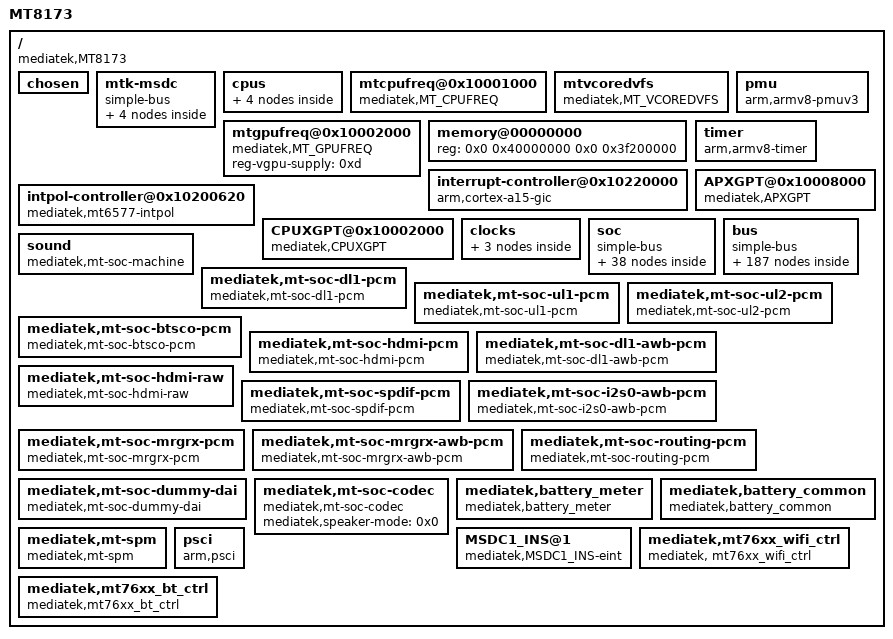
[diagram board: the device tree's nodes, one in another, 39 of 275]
/dts-v1/;

/memreserve/	0x0000000041e00000 0x0000000000a00000;
/memreserve/	0x0000000043f00000 0x0000000000010000;
/memreserve/	0x0000000043ff0000 0x0000000000010000;
/ {
	model = "MT8173";
	compatible = "mediatek,MT8173";
	interrupt-parent = <0x1>;
	#address-cells = <0x2>;
	#size-cells = <0x2>;

	chosen {
		bootargs = "console=tty0 console=ttyMT0,921600n1 root=/dev/ram initrd=0x44000000,0x600000 loglevel=8";
	};

	mtk-msdc {
		compatible = "simple-bus";
		#address-cells = <0x1>;
		#size-cells = <0x1>;
		ranges = <0x0 0x0 0x0 0xffffffff>;

		MSDC0@0x11230000 {
			compatible = "mediatek,MSDC0";
			reg = <0x11230000 0x10000 0x10001e84 0x2>;
			interrupts = <0x0 0x47 0x8>;
			msdc0-vemc-supply = <0x2>;
			#msdc0-vio18-supply = <0x3>;
			clocks = <0x4 0xe 0x5 0x26 0x6 0xe>;
			clock-names = "source", "mux_parent", "msdcpll2";
			id = <0x0>;
			status = "okay";
		};

		MSDC1@0x11240000 {
			compatible = "mediatek,MSDC1";
			reg = <0x11240000 0x10000 0x10001e84 0x2>;
			interrupts = <0x0 0x48 0x8>;
			msdc1-vmc-supply = <0x7>;
			msdc1-vmch-supply = <0x8>;
			clocks = <0x4 0xf>;
			clock-names = "source";
			id = <0x1>;
			status = "okay";
		};

		MSDC2@0x11250000 {
			compatible = "mediatek,MSDC2";
			reg = <0x11250000 0x10000 0x10001e84 0x2>;
			interrupts = <0x0 0x49 0x8>;
			msdc2-vmc-supply = <0x7>;
			msdc2-vmch-supply = <0x8>;
			clocks = <0x4 0x10>;
			clock-names = "source";
			id = <0x2>;
			status = "disabled";
		};

		MSDC3@0x11260000 {
			compatible = "mediatek,MSDC3";
			reg = <0x11260000 0x10000 0x10001e84 0x2>;
			interrupts = <0x0 0x4a 0x8>;
			clocks = <0x4 0x11>;
			clock-names = "source";
			id = <0x3>;
			status = "disabled";
		};
	};

	cpus {
		#address-cells = <0x1>;
		#size-cells = <0x0>;

		cpu@0 {
			device_type = "cpu";
			compatible = "arm,cortex-a53";
			reg = <0x0>;
			enable-method = "mt-boot";
			cpu-release-addr = <0x0 0x40000200>;
			clock-frequency = <0x3b9aca00>;
		};

		cpu@1 {
			device_type = "cpu";
			compatible = "arm,cortex-a53";
			reg = <0x1>;
			enable-method = "mt-boot";
			cpu-release-addr = <0x0 0x40000200>;
			clock-frequency = <0x3b9aca00>;
		};

		cpu@2 {
			device_type = "cpu";
			compatible = "arm,cortex-a57";
			reg = <0x100>;
			enable-method = "mt-boot";
			cpu-release-addr = <0x0 0x40000200>;
			clock-frequency = <0x3b9aca00>;
		};

		cpu@3 {
			device_type = "cpu";
			compatible = "arm,cortex-a57";
			reg = <0x101>;
			enable-method = "mt-boot";
			cpu-release-addr = <0x0 0x40000200>;
			clock-frequency = <0x3b9aca00>;
		};
	};

	mtcpufreq@0x10001000 {
		compatible = "mediatek,MT_CPUFREQ";
		reg-vpca53-supply = <0x9>;
		reg-ext-vpca57-supply = <0xa>;
		reg-vsramca57-supply = <0xb>;
		reg-vcore-supply = <0xc>;
		reg-vgpu-supply = <0xd>;
		clocks = <0x6 0x1>;
		clock-names = "mtcpufreq_apmixed_ca15pll";
	};

	mtvcoredvfs {
		compatible = "mediatek,MT_VCOREDVFS";
		reg-vcore-supply = <0xc>;
		clocks = <0x6 0x7 0x6 0xa 0x6 0x5 0x5 0x52 0x5 0x69 0x5 0x6c 0x5 0x3e 0x5 0x3f 0x5 0x43 0x5 0x2b 0x5 0x2c 0x5 0x4e 0x5 0x54 0x5 0x2e 0xe 0x5 0x67>;
		clock-names = "vencpll", "vcodecpll", "mmpll", "axi_sel", "venclt_sel", "cci400_sel", "univpll_d2", "univpll1_d2", "univpll2_d2", "syspll_d2", "syspll1_d2", "vcodecpll_370p5", "ddrphycfg_sel", "syspll1_d8", "clk26m", "scp_sel";
	};

	mtgpufreq@0x10002000 {
		compatible = "mediatek,MT_GPUFREQ";
		reg-vgpu-supply = <0xd>;
	};

	memory@00000000 {
		device_type = "memory";
		reg = <0x0 0x40000000 0x0 0x3f200000>;
	};

	pmu {
		compatible = "arm,armv8-pmuv3";
		interrupts = <0x0 0x8 0x4 0x0 0x9 0x4 0x0 0xa 0x4 0x0 0xb 0x4 0x0 0xc 0x4 0x0 0xd 0x4 0x0 0xe 0x4 0x0 0xf 0x4>;
	};

	interrupt-controller@0x10220000 {
		compatible = "arm,cortex-a15-gic", "arm,cortex-a9-gic";
		#interrupt-cells = <0x3>;
		#address-cells = <0x0>;
		interrupt-controller;
		reg = <0x0 0x10221000 0x0 0x1000 0x0 0x10222000 0x0 0x1000 0x0 0x10200620 0x0 0x1000>;
		interrupts = <0x1 0x9 0xf04>;
		linux,phandle = <0x1>;
		phandle = <0x1>;
	};

	intpol-controller@0x10200620 {
		compatible = "mediatek,mt6577-intpol";
		reg = <0x0 0x10200620 0x0 0x1000>;
		interrupt-controller;
	};

	CPUXGPT@0x10002000 {
		compatible = "mediatek,CPUXGPT";
		reg = <0x0 0x10200000 0x0 0x1000>;
		interrupts = <0x0 0x38 0x4 0x0 0x39 0x4 0x0 0x3a 0x4 0x0 0x3b 0x4 0x0 0x3c 0x4 0x0 0x3d 0x4 0x0 0x3e 0x4 0x0 0x3f 0x4>;
	};

	timer {
		compatible = "arm,armv8-timer";
		interrupts = <0x1 0xd 0x8 0x1 0xe 0x8 0x1 0xb 0x8 0x1 0xa 0x8>;
		clock-frequency = <0xc65d40>;
	};

	APXGPT@0x10008000 {
		compatible = "mediatek,APXGPT";
		reg = <0x0 0x10008000 0x0 0x1000>;
		interrupts = <0x0 0x90 0x8>;
		clock-frequency = <0xc65d40>;
	};

	clocks {

		clk_null {
			compatible = "fixed-clock";
			#clock-cells = <0x0>;
			clock-frequency = <0x0>;
		};

		clk26m {
			compatible = "fixed-clock";
			#clock-cells = <0x0>;
			clock-frequency = <0x18cba80>;
			linux,phandle = <0xe>;
			phandle = <0xe>;
		};

		clk32k {
			compatible = "fixed-clock";
			#clock-cells = <0x0>;
			clock-frequency = <0x7d00>;
		};
	};

	soc {
		compatible = "simple-bus";
		#address-cells = <0x2>;
		#size-cells = <0x2>;
		ranges;

		topckgen@10000000 {
			compatible = "mediatek,mt8173-topckgen";
			reg = <0x0 0x10000000 0x0 0x1000>;
			#clock-cells = <0x1>;
			linux,phandle = <0x5>;
			phandle = <0x5>;
		};

		infrasys@10001000 {
			compatible = "mediatek,mt8173-infrasys";
			reg = <0x0 0x10001000 0x0 0x1000>;
			#clock-cells = <0x1>;
			linux,phandle = <0x12>;
			phandle = <0x12>;
		};

		perisys@10003000 {
			compatible = "mediatek,mt8173-perisys";
			reg = <0x0 0x10003000 0x0 0x1000>;
			#clock-cells = <0x1>;
			linux,phandle = <0x4>;
			phandle = <0x4>;
		};

		apmixedsys@10209000 {
			compatible = "mediatek,mt8173-apmixedsys";
			reg = <0x0 0x10209000 0x0 0x1000>;
			#clock-cells = <0x1>;
			linux,phandle = <0x6>;
			phandle = <0x6>;
		};

		audiosys@112200000 {
			compatible = "mediatek,mt8173-audiosys";
			reg = <0x0 0x11220000 0x0 0x1000>;
			#clock-cells = <0x1>;
			linux,phandle = <0x1c>;
			phandle = <0x1c>;
		};

		mfgsys@13fff000 {
			compatible = "mediatek,mt8173-mfgsys";
			reg = <0x0 0x13fff000 0x0 0x1000>;
			#clock-cells = <0x1>;
			linux,phandle = <0x16>;
			phandle = <0x16>;
		};

		mmsys@14000000 {
			compatible = "mediatek,mt8173-mmsys";
			reg = <0x0 0x14000000 0x0 0x1000>;
			#clock-cells = <0x1>;
			linux,phandle = <0x13>;
			phandle = <0x13>;
		};

		imgsys@15000000 {
			compatible = "mediatek,mt8173-imgsys";
			reg = <0x0 0x15000000 0x0 0x1000>;
			#clock-cells = <0x1>;
			linux,phandle = <0x19>;
			phandle = <0x19>;
		};

		vdecsys@16000000 {
			compatible = "mediatek,mt8173-vdecsys";
			reg = <0x0 0x16000000 0x0 0x1000>;
			#clock-cells = <0x1>;
			linux,phandle = <0x18>;
			phandle = <0x18>;
		};

		vencsys@18000000 {
			compatible = "mediatek,mt8173-vencsys";
			reg = <0x0 0x18000000 0x0 0x1000>;
			#clock-cells = <0x1>;
			linux,phandle = <0x1a>;
			phandle = <0x1a>;
		};

		vencltsys@19000000 {
			compatible = "mediatek,mt8173-vencltsys";
			reg = <0x0 0x19000000 0x0 0x1000>;
			#clock-cells = <0x1>;
			linux,phandle = <0x1b>;
			phandle = <0x1b>;
		};

		scpsys@10001000 {
			compatible = "mediatek,mt8173-scpsys";
			reg = <0x0 0x10001000 0x0 0x1000 0x0 0x10006000 0x0 0x1000 0x0 0x13fff000 0x0 0x1000>;
			#clock-cells = <0x1>;
			linux,phandle = <0x14>;
			phandle = <0x14>;
		};

		pmic {
			compatible = "mediatek,mt6397";
			interrupt-parent = <0xf>;
			interrupts = <0x5 0x4>;

			mediatek,pmic-mt6397 {
				compatible = "mediatek,pmic-mt6397";
			};

			regulators {

				buck_vpca15 {
					regulator-name = "vpca15";
					regulator-min-microvolt = <0xaae60>;
					regulator-max-microvolt = <0x16caf6>;
					regulator-ramp-delay = <0x30d4>;
					regulator-enable-ramp-delay = <0xc8>;
					regulator-always-on;
					regulator-boot-on;
					linux,phandle = <0x9>;
					phandle = <0x9>;
				};

				buck_vpca7 {
					regulator-name = "vpca7";
					regulator-min-microvolt = <0xaae60>;
					regulator-max-microvolt = <0x16caf6>;
					regulator-ramp-delay = <0x30d4>;
					regulator-enable-ramp-delay = <0x73>;
					regulator-always-on;
					regulator-boot-on;
				};

				buck_vsramca15 {
					regulator-name = "vsramca15";
					regulator-min-microvolt = <0xaae60>;
					regulator-max-microvolt = <0x16caf6>;
					regulator-ramp-delay = <0x30d4>;
					regulator-enable-ramp-delay = <0x73>;
					regulator-always-on;
					regulator-boot-on;
				};

				buck_vsramca7 {
					regulator-name = "vsramca7";
					regulator-min-microvolt = <0xaae60>;
					regulator-max-microvolt = <0x16caf6>;
					regulator-ramp-delay = <0x30d4>;
					regulator-enable-ramp-delay = <0xd7>;
					regulator-boot-on;
					linux,phandle = <0xb>;
					phandle = <0xb>;
				};

				buck_vcore {
					regulator-name = "vcore";
					regulator-min-microvolt = <0xaae60>;
					regulator-max-microvolt = <0x16caf6>;
					regulator-ramp-delay = <0x30d4>;
					regulator-enable-ramp-delay = <0x73>;
					regulator-always-on;
					regulator-boot-on;
					linux,phandle = <0xc>;
					phandle = <0xc>;
				};

				buck_vgpu {
					regulator-name = "vgpu";
					regulator-min-microvolt = <0xaae60>;
					regulator-max-microvolt = <0x16caf6>;
					regulator-ramp-delay = <0x30d4>;
					regulator-enable-ramp-delay = <0x73>;
				};

				buck_vdrm {
					regulator-name = "vdrm";
					regulator-min-microvolt = <0xc3500>;
					regulator-max-microvolt = <0x185196>;
					regulator-ramp-delay = <0x30d4>;
					regulator-enable-ramp-delay = <0x1f4>;
					regulator-always-on;
					regulator-boot-on;
				};

				buck_vio18 {
					regulator-name = "vio18";
					regulator-min-microvolt = <0x1b7740>;
					regulator-max-microvolt = <0x1b7740>;
					regulator-ramp-delay = <0x30d4>;
					regulator-enable-ramp-delay = <0x1f4>;
					regulator-always-on;
					regulator-boot-on;
					linux,phandle = <0x3>;
					phandle = <0x3>;
				};

				ldo_vtcxo {
					regulator-name = "vtcxo";
					regulator-min-microvolt = <0x2ab980>;
					regulator-max-microvolt = <0x2ab980>;
					regulator-enable-ramp-delay = <0x5a>;
					regulator-always-on;
					regulator-boot-on;
				};

				ldo_va28 {
					regulator-name = "va28";
					regulator-min-microvolt = <0x2ab980>;
					regulator-max-microvolt = <0x2ab980>;
					regulator-enable-ramp-delay = <0xda>;
					regulator-always-on;
					regulator-boot-on;
				};

				ldo_vcama {
					regulator-name = "vcama";
					regulator-min-microvolt = <0x16e360>;
					regulator-max-microvolt = <0x2ab980>;
					regulator-enable-ramp-delay = <0xda>;
				};

				ldo_vio28 {
					regulator-name = "vio28";
					regulator-min-microvolt = <0x2ab980>;
					regulator-max-microvolt = <0x2ab980>;
					regulator-enable-ramp-delay = <0xf0>;
					regulator-always-on;
					regulator-boot-on;
				};

				ldo_usb {
					regulator-name = "usb";
					regulator-min-microvolt = <0x325aa0>;
					regulator-max-microvolt = <0x325aa0>;
					regulator-enable-ramp-delay = <0xda>;
					linux,phandle = <0x17>;
					phandle = <0x17>;
				};

				ldo_vmc {
					regulator-name = "vmc";
					regulator-min-microvolt = <0x1b7740>;
					regulator-max-microvolt = <0x325aa0>;
					regulator-enable-ramp-delay = <0xda>;
					linux,phandle = <0x7>;
					phandle = <0x7>;
				};

				ldo_vmch {
					regulator-name = "vmch";
					regulator-min-microvolt = <0x2dc6c0>;
					regulator-max-microvolt = <0x325aa0>;
					regulator-enable-ramp-delay = <0xda>;
					linux,phandle = <0x8>;
					phandle = <0x8>;
				};

				ldo_vemc3v3 {
					regulator-name = "vemc_3v3";
					regulator-min-microvolt = <0x2dc6c0>;
					regulator-max-microvolt = <0x325aa0>;
					regulator-enable-ramp-delay = <0xda>;
					regulator-boot-on;
					linux,phandle = <0x2>;
					phandle = <0x2>;
				};

				ldo_vcamd {
					regulator-name = "vgp1";
					regulator-min-microvolt = <0x129da0>;
					regulator-max-microvolt = <0x325aa0>;
					regulator-enable-ramp-delay = <0xf0>;
					regulator-always-on;
					regulator-boot-on;
				};

				ldo_vcamio {
					regulator-name = "vgp2";
					regulator-min-microvolt = <0x124f80>;
					regulator-max-microvolt = <0x325aa0>;
					regulator-enable-ramp-delay = <0xda>;
				};

				ldo_vcamaf {
					regulator-name = "vgp3";
					regulator-min-microvolt = <0x124f80>;
					regulator-max-microvolt = <0x325aa0>;
					regulator-enable-ramp-delay = <0xda>;
				};

				ldo_vgp4 {
					regulator-name = "vgp4";
					regulator-min-microvolt = <0x124f80>;
					regulator-max-microvolt = <0x325aa0>;
					regulator-enable-ramp-delay = <0xda>;
				};

				ldo_vgp5 {
					regulator-name = "vgp5";
					regulator-min-microvolt = <0x124f80>;
					regulator-max-microvolt = <0x2dc6c0>;
					regulator-enable-ramp-delay = <0xda>;
				};

				ldo_vgp6 {
					regulator-name = "vgp6";
					regulator-min-microvolt = <0x124f80>;
					regulator-max-microvolt = <0x325aa0>;
					regulator-enable-ramp-delay = <0xda>;
				};

				ldo_vibr {
					regulator-name = "vibr";
					regulator-min-microvolt = <0x124f80>;
					regulator-max-microvolt = <0x325aa0>;
					regulator-enable-ramp-delay = <0xda>;
				};
			};
		};
	};

	bus {
		compatible = "simple-bus";
		#address-cells = <0x1>;
		#size-cells = <0x1>;
		ranges = <0x0 0x0 0x0 0xffffffff>;

		CHIPID@08000000 {
			compatible = "mediatek,CHIPID";
			reg = <0x8000000 0x10>;
		};

		TOPCKGEN@0x10000000 {
			compatible = "mediatek,TOPCKGEN";
			reg = <0x10000000 0x1000>;
		};

		INFRACFG_AO@0x10001000 {
			compatible = "mediatek,INFRACFG_AO";
			reg = <0x10001000 0x1000>;
		};

		IOCFG_L@0x10002000 {
			compatible = "mediatek,IOCFG_L";
			reg = <0x10002000 0x400>;
		};

		IOCFG_B@0x10002400 {
			compatible = "mediatek,IOCFG_B";
			reg = <0x10002400 0x400>;
		};

		IOCFG_R@0x10002800 {
			compatible = "mediatek,IOCFG_R";
			reg = <0x10002800 0x400>;
		};

		IOCFG_T@0x10002C00 {
			compatible = "mediatek,IOCFG_T";
			reg = <0x10002c00 0x400>;
		};

		PERICFG@0x10003000 {
			compatible = "mediatek,PERICFG";
			reg = <0x10003000 0x1000>;
		};

		DRAMC0@0x10004000 {
			compatible = "mediatek,DRAMC0";
			reg = <0x10004000 0x1000>;
		};

		DRAMC1@0x10011000 {
			compatible = "mediatek,DRAMC1";
			reg = <0x10011000 0x1000>;
		};

		GPIO@0x10005000 {
			compatible = "mediatek,GPIO";
			reg = <0x10005000 0xe70>;
		};

		pcfg_pull_none {
			bias-disable;
		};

		pcfg_pull_down {
			bias-pull-down;
		};

		pcfg_pull_up {
			bias-pull-up;
			linux,phandle = <0x11>;
			phandle = <0x11>;
		};

		pcfg_output_low {
			output-low;
		};

		pcfg_output_high {
			output-high;
		};

		pcfg_input_enable {
			input-enable;
		};

		pcfg_input_disable {
			input-disable;
		};

		pcfg_input_pulldisable {
			input-enable;
			bias-disable;
		};

		pcfg_input_pullup {
			input-enable;
			bias-pull-up;
		};

		pcfg_input_pulldown {
			input-enable;
			bias-pull-down;
		};

		pinctrl@0x10005000 {
			compatible = "mediatek,mt8173-pinctrl";
			reg = <0x10005000 0x1000>;
			gpio-controller;
			#gpio-cells = <0x2>;
			pinctrl-names = "default";
			pinctrl-0 = <0x10>;

			pinctrl@0x10005000 {
				linux,phandle = <0x10>;
				phandle = <0x10>;
			};

			bt_wake_up {
				mediatek,pins = <0x6400 0x11>;
				linux,phandle = <0x1d>;
				phandle = <0x1d>;
			};
		};

		pinctrl@0x0000C000 {
			compatible = "mediatek,mt6397-pinctrl";
			reg = <0xc000 0x108>;
			gpio-controller;
			#gpio-cells = <0x2>;
			linux,phandle = <0x15>;
			phandle = <0x15>;
		};

		SLEEP@0x10006000 {
			compatible = "mediatek,SLEEP";
			reg = <0x10006000 0x1000>;
			interrupts = <0x0 0x9b 0x8 0x0 0x9c 0x8 0x0 0x9d 0x8 0x0 0x9e 0x8 0x0 0x9f 0x8 0x0 0xa0 0x8>;
		};

		TOPRGU@0x10007000 {
			compatible = "mediatek,TOPRGU";
			reg = <0x10007000 0x1000>;
			interrupts = <0x0 0x78 0x2>;
		};

		RSVD@0x10009000 {
			compatible = "mediatek,RSVD";
			reg = <0x10009000 0x1000>;
		};

		SEJ@0x1000A000 {
			compatible = "mediatek,SEJ";
			reg = <0x1000a000 0x1000>;
			interrupts = <0x0 0xa3 0x8>;
		};

		EINTC@0x1000B000 {
			compatible = "mediatek,EINTC";
			reg = <0x1000b000 0x1000>;
			interrupts = <0x0 0x91 0x4>;
			#interrupt-cells = <0x2>;
			interrupt-controller;
			linux,phandle = <0xf>;
			phandle = <0xf>;
		};

		APMIXED@0x10209000 {
			compatible = "mediatek,APMIXED";
			reg = <0x10209000 0x1000>;
			interrupts = <0x0 0x81 0x1>;
		};

		FHCTL@0x10209E00 {
			compatible = "mediatek,FHCTL";
			reg = <0x10209e00 0x100>;
		};

		PWRAP@0x1000D000 {
			compatible = "mediatek,PWRAP";
			reg = <0x1000d000 0x1000>;
			interrupts = <0x0 0x99 0x4>;
		};

		DEVAPC_AO@0x1000E000 {
			compatible = "mediatek,DEVAPC_AO";
			reg = <0x1000e000 0x1000>;
		};

		DDRPHY0@0x1000F000 {
			compatible = "mediatek,DDRPHY0";
			reg = <0x1000f000 0x1000>;
		};

		DDRPHY1@0x10012000 {
			compatible = "mediatek,DDRPHY1";
			reg = <0x10012000 0x1000>;
		};

		CQDMA@0x10212C00 {
			compatible = "mediatek,CQDMA";
			reg = <0x10212c00 0x1000>;
			interrupts = <0x0 0x8f 0x8>;
			nr_channel = <0x1>;
		};

		KP@0x10010000 {
			compatible = "mediatek,KP";
			reg = <0x10010000 0x1000>;
			interrupts = <0x0 0x9a 0x2>;
		};

		TOPMISC@0x10011000 {
			compatible = "mediatek,TOPMISC";
			reg = <0x10011000 0x1000>;
		};

		SCP_SRAM@0x10020000 {
			compatible = "mediatek,SCP_SRAM";
			reg = <0x10020000 0x30000>;
		};

		SCP_CFGREG@0x10050000 {
			compatible = "mediatek,SCP_CFGREG";
			reg = <0x10050000 0x90>;
			interrupts = <0x0 0xa6 0x4>;
		};

		DBG_ETB@0x10100000 {
			compatible = "mediatek,DBG_ETB";
			reg = <0x10410000 0x10000 0x10430000 0x10000 0x10440000 0x10000 0x104a0000 0x10000>;
		};

		DBG_DEBUG {
			compatible = "mediatek,DBG_DEBUG";
			num = <0x8>;
			reg = <0x10810000 0x1000 0x10910000 0x1000 0x10a10000 0x1000 0x10b10000 0x1000 0x10c10000 0x1000 0x10d10000 0x1000 0x10e10000 0x1000 0x10f10000 0x1000>;
		};

		DBG_ETM {
			compatible = "mediatek,DBG_ETM";
			num = <0x8>;
			reg = <0x10840000 0x1000 0x10940000 0x1000 0x10a40000 0x1000 0x10b40000 0x1000 0x10c40000 0x1000 0x10d40000 0x1000 0x10e40000 0x1000 0x10f40000 0x1000>;
		};

		MCUCFG@0x10200000 {
			compatible = "mediatek,MCUCFG";
			reg = <0x10200000 0x1000>;
		};

		INFRACFG@0x10201000 {
			compatible = "mediatek,INFRACFG";
			reg = <0x10201000 0x1000>;
		};

		SRAMROM@0x10202000 {
			compatible = "mediatek,SRAMROM";
			reg = <0x10202000 0x1000>;
		};

		EMI@0x10203000 {
			compatible = "mediatek,EMI";
			reg = <0x10203000 0x1000>;
			interrupts = <0x0 0x80 0x8>;
		};

		SYS_CIRQ@0x10204000 {
			compatible = "mediatek,SYS_CIRQ";
			reg = <0x10204000 0x1000>;
		};

		M4U@0x10205000 {
			cell-index = <0x0>;
			compatible = "mediatek,M4U";
			reg = <0x10205000 0x1000>;
			interrupts = <0x0 0x8b 0x8>;
			clocks = <0x12 0x6 0x12 0x2>;
			clock-names = "infra_m4u", "infra_smi";
		};

		EFUSEC@0x10206000 {
			compatible = "mediatek,EFUSEC";
			reg = <0x10206000 0x1000>;
			interrupts = <0x0 0x82 0x1>;
		};

		DEVAPC@0x10207000 {
			compatible = "mediatek,DEVAPC";
			reg = <0x10207000 0x1000>;
			interrupts = <0x0 0x7e 0x8>;
		};

		BUS_DBG@0x10208000 {
			compatible = "mediatek,BUS_DBG";
			reg = <0x10208000 0x1000>;
			interrupts = <0x0 0x7d 0x8>;
		};

		AP_CCIF0@0x10209000 {
			compatible = "mediatek,AP_CCIF0";
			reg = <0x10209000 0x1000>;
			interrupts = <0x0 0x84 0x8>;
		};

		INFRA_MBIST@0x1020D000 {
			compatible = "mediatek,INFRA_MBIST";
			reg = <0x1020d000 0x1000>;
		};

		DRAMC0_NAO@0x1020E000 {
			compatible = "mediatek,DRAMC0_NAO";
			reg = <0x1020e000 0x1000>;
		};

		DRAMC1_NAO@0x10213000 {
			compatible = "mediatek,DRAMC1_NAO";
			reg = <0x10213000 0x1000>;
		};

		EMI_DVFS_SRAM@0x0012FC00 {
			compatible = "mediatek,EMI_DVFS_SRAM";
			reg = <0x12fc00 0x400>;
		};

		TRNG@0x1020F000 {
			compatible = "mediatek,TRNG";
			reg = <0x1020f000 0x1000>;
			interrupts = <0x0 0x85 0x8>;
		};

		GCPU@0x10210000 {
			compatible = "mediatek,GCPU";
			reg = <0x10210000 0x1000>;
			interrupts = <0x0 0x8e 0x8>;
		};

		MD2MD_MD1_CCIF0@0x10211000 {
			compatible = "mediatek,MD2MD_MD1_CCIF0";
			reg = <0x10211000 0x1000>;
		};

		GCE@0x10212000 {
			compatible = "mediatek,GCE";
			reg = <0x10212000 0x1000>;
			interrupts = <0x0 0x87 0x8 0x0 0x88 0x8>;
			clocks = <0x12 0x4 0x13 0xf 0x13 0x1 0x13 0x2 0x13 0x32 0x13 0x3 0x13 0x4 0x13 0x5 0x13 0x6 0x13 0x7 0x13 0x8 0x13 0x9 0x13 0xa 0x13 0xc 0x13 0xd 0x13 0xb 0x14 0x1 0x14 0x4 0x14 0x5>;
			clock-names = "MT_CG_INFRA_GCE", "MT_CG_DISP0_MUTEX_32K", "MT_CG_DISP0_SMI_COMMON", "MT_CG_DISP0_SMI_LARB0", "MT_CG_DISP0_SMI_LARB4", "MT_CG_DISP0_CAM_MDP", "MT_CG_DISP0_MDP_RDMA0", "MT_CG_DISP0_MDP_RDMA1", "MT_CG_DISP0_MDP_RSZ0", "MT_CG_DISP0_MDP_RSZ1", "MT_CG_DISP0_MDP_RSZ2", "MT_CG_DISP0_MDP_TDSHP0", "MT_CG_DISP0_MDP_TDSHP1", "MT_CG_DISP0_MDP_WROT0", "MT_CG_DISP0_MDP_WROT1", "MT_CG_DISP0_MDP_WDMA", "sys_vde", "sys_isp", "sys_dis";
		};

		MD2MD_MD2_CCIF0@0x10213000 {
			compatible = "mediatek,MD2MD_MD2_CCIF0";
			reg = <0x10213000 0x1000>;
		};

		PERISYS_IOMMU@0x10214000 {
			cell-index = <0x1>;
			compatible = "mediatek,PERISYS_IOMMU";
			reg = <0x10214000 0x1000>;
			interrupts = <0x0 0x89 0x8>;
		};

		MIPI_TX0@0x10215000 {
			compatible = "mediatek,MIPI_TX0";
			reg = <0x10215000 0x1000>;
		};

		MIPI_RX_ANA_CSI0@0x10217000 {
			compatible = "mediatek,MIPI_RX_ANA_CSI0";
			reg = <0x10217000 0x1000>;
			interrupts = <0x0 0x6a 0x1>;
		};

		MIPI_RX_ANA_CSI1@0x10218000 {
			compatible = "mediatek,MIPI_RX_ANA_CSI1";
			reg = <0x10218000 0x1000>;
		};

		GIC@0x10220000 {
			compatible = "mediatek,GIC";
			reg = <0x10220000 0x8000>;
		};

		CCI400@0x10390000 {
			compatible = "mediatek,CCI400";
			reg = <0x10390000 0x10000>;
		};

		DBGAPB@0x10400000 {
			compatible = "mediatek,DBGAPB";
			reg = <0x10400000 0xc00000>;
			interrupts = <0x0 0x63 0x8>;
		};

		AP_DMA@0x11000000 {
			compatible = "mediatek,AP_DMA";
			reg = <0x11000000 0x1000>;
			interrupts = <0x0 0x59 0x8>;
		};

		AUXADC@0x11001000 {
			compatible = "mediatek,AUXADC";
			reg = <0x11001000 0x1000>;
			interrupts = <0x0 0x44 0x2>;
			clocks = <0x4 0x1d>;
			clock-names = "auxadc_clk";
		};

		AP_DMA_UART0_TX@0x11000300 {
			compatible = "mediatek,AP_DMA_UART0_TX";
			reg = <0x11000300 0x80>;
			interrupts = <0x0 0x5f 0x8>;
			clocks = <0x4 0xd>;
			clock-names = "MT_CG_PERI_dma";
		};

		AP_DMA_UART0_RX@0x11000380 {
			compatible = "mediatek,AP_DMA_UART0_RX";
			reg = <0x11000380 0x80>;
			interrupts = <0x0 0x60 0x8>;
			clocks = <0x4 0xd>;
			clock-names = "MT_CG_PERI_dma";
		};

		AP_DMA_UART1_TX@0x11000400 {
			compatible = "mediatek,AP_DMA_UART1_TX";
			reg = <0x11000400 0x80>;
			interrupts = <0x0 0x61 0x8>;
			clocks = <0x4 0xd>;
			clock-names = "MT_CG_PERI_dma";
		};

		AP_DMA_UART1_RX@0x11000480 {
			compatible = "mediatek,AP_DMA_UART1_RX";
			reg = <0x11000480 0x80>;
			interrupts = <0x0 0x62 0x8>;
			clocks = <0x4 0xd>;
			clock-names = "MT_CG_PERI_dma";
		};

		AP_DMA_UART2_TX@0x11000500 {
			compatible = "mediatek,AP_DMA_UART2_TX";
			reg = <0x11000500 0x80>;
			interrupts = <0x0 0x63 0x8>;
			clocks = <0x4 0xd>;
			clock-names = "MT_CG_PERI_dma";
		};

		AP_DMA_UART2_RX@0x11000580 {
			compatible = "mediatek,AP_DMA_UART2_RX";
			reg = <0x11000580 0x80>;
			interrupts = <0x0 0x64 0x8>;
			clocks = <0x4 0xd>;
			clock-names = "MT_CG_PERI_dma";
		};

		AP_DMA_UART3_TX@0x11000600 {
			compatible = "mediatek,AP_DMA_UART3_TX";
			reg = <0x11000600 0x80>;
			interrupts = <0x0 0x65 0x8>;
			clocks = <0x4 0xd>;
			clock-names = "MT_CG_PERI_dma";
		};

		AP_DMA_UART3_RX@0x11000680 {
			compatible = "mediatek,AP_DMA_UART3_RX";
			reg = <0x11000680 0x80>;
			interrupts = <0x0 0x66 0x8>;
			clocks = <0x4 0xd>;
			clock-names = "MT_CG_PERI_dma";
		};

		AP_UART0@0x11002000 {
			cell-index = <0x0>;
			compatible = "mediatek,AP_UART0";
			reg = <0x11002000 0x1000>;
			interrupts = <0x0 0x53 0x8>;
			clocks = <0x4 0x14>;
			clock-names = "MT_CG_PERI_UART0";
		};

		AP_UART1@0x11003000 {
			cell-index = <0x1>;
			compatible = "mediatek,AP_UART1";
			reg = <0x11003000 0x1000>;
			interrupts = <0x0 0x54 0x8>;
			clocks = <0x4 0x15>;
			clock-names = "MT_CG_PERI_UART1";
		};

		AP_UART2@0x11004000 {
			cell-index = <0x2>;
			compatible = "mediatek,AP_UART2";
			reg = <0x11004000 0x1000>;
			interrupts = <0x0 0x55 0x8>;
			clocks = <0x4 0x16>;
			clock-names = "MT_CG_PERI_UART2";
		};

		AP_UART3@0x11005000 {
			cell-index = <0x3>;
			compatible = "mediatek,AP_UART3";
			reg = <0x11005000 0x1000>;
			interrupts = <0x0 0x56 0x8>;
			clocks = <0x4 0x17>;
			clock-names = "MT_CG_PERI_UART3";
		};

		PWM@0x11006000 {
			compatible = "mediatek,PWM";
			reg = <0x11006000 0x1000>;
			interrupts = <0x0 0x45 0x8>;
			clocks = <0x4 0x3 0x4 0x4 0x4 0x5 0x4 0x6 0x4 0x7 0x4 0x8 0x4 0x9 0x4 0xa>;
			clock-names = "MT_CG_PERI_PWM1", "MT_CG_PERI_PWM2", "MT_CG_PERI_PWM3", "MT_CG_PERI_PWM4", "MT_CG_PERI_PWM5", "MT_CG_PERI_PWM6", "MT_CG_PERI_PWM7", "MT_CG_PERI_PWM";
		};

		I2C0@0x11007000 {
			compatible = "mediatek,mt8173-i2c";
			#address-cells = <0x1>;
			#size-cells = <0x0>;
			reg = <0x11007000 0x70 0x11000100 0x80>;
			interrupts = <0x0 0x4c 0x8>;
			id = <0x0>;
			clock-frequency = <0x186a0>;
			clock-div = <0x10>;
			mediatek,have-dcm;
			clocks = <0x4 0x18 0x4 0xd>;
			clock-names = "main", "dma";
		};

		I2C1@0x11008000 {
			compatible = "mediatek,mt8173-i2c";
			#address-cells = <0x1>;
			#size-cells = <0x0>;
			reg = <0x11008000 0x70 0x11000180 0x80>;
			interrupts = <0x0 0x4d 0x8>;
			id = <0x1>;
			clock-frequency = <0x16e360>;
			clock-div = <0x10>;
			mediatek,have-dcm;
			mediatek,use-push-pull;
			clocks = <0x4 0x19 0x4 0xd>;
			clock-names = "main", "dma";

			da9212-regulator {
				#address-cells = <0x0>;
				compatible = "dlg,da9212-regulator";
				reg = <0x68>;

				regulators {

					BUCKA {
						regulator-name = "VBUCKA";
						regulator-min-microvolt = <0xaae60>;
						regulator-max-microvolt = <0x13fd30>;
						regulator-min-microamp = <0x1e8480>;
						regulator-max-microamp = <0x432380>;
						regulator-ramp-delay = <0x2710>;
						en-gpio = <0x15 0x19 0x0>;
						linux,phandle = <0xa>;
						phandle = <0xa>;
					};

					BUCKB {
						regulator-name = "VBUCKB";
						regulator-min-microvolt = <0xaae60>;
						regulator-max-microvolt = <0x13fd30>;
						regulator-min-microamp = <0x1e8480>;
						regulator-max-microamp = <0x2dc6c0>;
						regulator-ramp-delay = <0x2710>;
						en-gpio = <0x15 0x18 0x0>;
						linux,phandle = <0xd>;
						phandle = <0xd>;
					};
				};
			};
		};

		I2C2@0x11009000 {
			compatible = "mediatek,mt8173-i2c";
			#address-cells = <0x1>;
			#size-cells = <0x0>;
			reg = <0x11009000 0x70 0x11000200 0x80>;
			interrupts = <0x0 0x4e 0x8>;
			id = <0x2>;
			clock-frequency = <0x186a0>;
			clock-div = <0x10>;
			mediatek,have-dcm;
			clocks = <0x4 0x1a 0x4 0xd>;
			clock-names = "main", "dma";
		};

		I2C3@0x11010000 {
			compatible = "mediatek,mt8173-i2c";
			#address-cells = <0x1>;
			#size-cells = <0x0>;
			reg = <0x11010000 0x70 0x11000280 0x80>;
			interrupts = <0x0 0x4f 0x8>;
			id = <0x3>;
			clock-frequency = <0x186a0>;
			clock-div = <0x10>;
			mediatek,have-dcm;
			clocks = <0x4 0x1b 0x4 0xd>;
			clock-names = "main", "dma";

			bq24297_charger@6B {
				compatible = "ti,bq24297";
				reg = <0x6b>;
			};
		};

		I2C4@0x11011000 {
			compatible = "mediatek,mt8173-i2c";
			#address-cells = <0x1>;
			#size-cells = <0x0>;
			reg = <0x11011000 0x70 0x11000300 0x80>;
			interrupts = <0x0 0x50 0x8>;
			id = <0x4>;
			clock-frequency = <0x186a0>;
			clock-div = <0x10>;
			mediatek,have-dcm;
			clocks = <0x4 0x1c 0x4 0xd>;
			clock-names = "main", "dma";

			tmp103-sensor@70 {
				compatible = "ti,tmp103_temp_sensor";
				reg = <0x70>;
				offset = <0x125c>;
				alpha = <0x3>;
				weight = <0x190>;
			};

			tmp103-sensor@71 {
				compatible = "ti,tmp103_temp_sensor";
				reg = <0x71>;
				offset = <0xd48>;
				alpha = <0x3e8>;
				weight = <0x0>;
			};

			tmp103-sensor@72 {
				compatible = "ti,tmp103_temp_sensor";
				reg = <0x72>;
				offset = <0x578>;
				alpha = <0x1>;
				weight = <0x258>;
			};

			lp5562@30 {
				compatible = "ti,lp5562";
				reg = <0x30>;
				clock-mode = [02];

				chan0 {
					chan-name = [52 00];
					led-cur = [c1];
					max-cur = [c8];
				};

				chan1 {
					chan-name = [47 00];
					led-cur = [c1];
					max-cur = [c8];
				};

				chan2 {
					chan-name = [42 00];
					led-cur = [c1];
					max-cur = [c8];
				};

				chan3 {
					chan-name = [57 00];
					led-cur = [c1];
					max-cur = [c8];
				};
			};
		};

		I2C6@0x11013000 {
			compatible = "mediatek,mt8173-i2c";
			#address-cells = <0x1>;
			#size-cells = <0x0>;
			reg = <0x11013000 0x70 0x11000080 0x80>;
			interrupts = <0x0 0x52 0x8>;
			id = <0x6>;
			clock-frequency = <0x186a0>;
			clock-div = <0x10>;
			mediatek,have-dcm;
			clocks = <0x4 0x23 0x4 0xd>;
			clock-names = "main", "dma";
		};

		SPI0@0x1100A000 {
			compatible = "mediatek,SPI0";
			cell-index = <0x0>;
			reg = <0x1100a000 0x1000>;
			interrupts = <0x0 0x6e 0x8>;
			clocks = <0x4 0x1e>;
			clock-names = "PERISYS_PERI_SPI0";
		};

		THERM_CTRL@0x1100B000 {
			compatible = "mediatek,THERM_CTRL";
			reg = <0x1100b000 0x1000>;
			interrupts = <0x0 0x46 0x8>;
			clocks = <0x4 0x2>;
			clock-names = "PERISYS_PERI_THERM";
		};

		PTP_FSM@0x1100B000 {
			compatible = "mediatek,PTP_FSM";
			reg = <0x1100b000 0x1000>;
			interrupts = <0x0 0x75 0x8>;
			reg-vcore-supply = <0xc>;
			clocks = <0x4 0x2 0x5 0x43 0x16 0x1 0x5 0x52>;
			clock-names = "ptp_peri_therm", "univpll2_d2", "ptp_mfg_axi", "axi_sel";
		};

		AP_DMA_BTIF_TX@0x11000700 {
			compatible = "mediatek,AP_DMA_BTIF_TX";
			reg = <0x11000700 0x80>;
			interrupts = <0x0 0x51 0x8>;
		};

		AP_DMA_BTIF_RX@0x11000780 {
			compatible = "mediatek,AP_DMA_BTIF_RX";
			reg = <0x11000780 0x80>;
			interrupts = <0x0 0x51 0x8>;
		};

		BTIF@0x1100C000 {
			compatible = "mediatek,BTIF";
			reg = <0x1100c000 0x1000>;
			interrupts = <0x0 0x52 0x8>;
		};

		NFI@0x1100D000 {
			compatible = "mediatek,NFI";
			reg = <0x1100d000 0x1000>;
			interrupts = <0x0 0x58 0x8>;
		};

		NFIECC@0x1100E000 {
			compatible = "mediatek,NFIECC";
			reg = <0x1100e000 0x1000>;
			interrupts = <0x0 0x57 0x8>;
		};

		SSUSB@0x11270000 {
			compatible = "mediatek,ssusb";
			cell-index = <0x0>;
			reg = <0x11270000 0x1000 0x11271000 0x3000 0x11280000 0x20000>;
			interrupts = <0x0 0x73 0x8 0x0 0x40 0x8>;
			reg-vusb33-supply = <0x17>;
			usb-xtal-clk = <0x6>;
			usb-wakeup-ctrl = <0x4>;
			clocks = <0x14 0xa 0x4 0xb 0x4 0xc>;
			clock-names = "scp_sys_usb", "peri_usb0", "peri_usb1";
			num-eps = <0x9>;
			port-num = <0x2>;
			drv-mode = <0x3>;
			str-mode = <0x1>;
			otg-mode = <0x2>;
			is-u3-otg = <0x0>;
			wakeup-src = <0x2>;
			init-as-host = <0x0>;
			p0-vbus-mode = <0x2>;
			p0-gpio = <0x15 0xd 0x0>;
			p1-vbus-mode = <0x0>;
		};

		AUDIO@0x11220000 {
			compatible = "mediatek,AUDIO";
			reg = <0x11220000 0x10000>;
			interrupts = <0x0 0x86 0x8>;
		};

		HAN@0x13000000 {
			compatible = "mediatek,HAN";
			reg = <0x13000000 0xffff 0x13fff000 0x1000>;
			interrupts = <0x0 0xd9 0x8>;
			interrupt-names = "RGX";
			clock-frequency = <0x23c34600>;
			clocks = <0x14 0x2 0x16 0x1 0x16 0x2 0x16 0x3 0x16 0x4>;
			clock-names = "MT_CG_MFG_POWER", "MT_CG_MFG_AXI", "MT_CG_MFG_MEM", "MT_CG_MFG_G3D", "MT_CG_MFG_26M";
		};

		MMSYS_CONFIG@0x14000000 {
			compatible = "mediatek,MMSYS_CONFIG";
			reg = <0x14000000 0x1000>;
		};

		MDP_RDMA0@0x14001000 {
			compatible = "mediatek,MDP_RDMA0";
			reg = <0x14001000 0x1000>;
			interrupts = <0x0 0xaa 0x8>;
		};

		MDP_RDMA1@0x14002000 {
			compatible = "mediatek,MDP_RDMA1";
			reg = <0x14002000 0x1000>;
			interrupts = <0x0 0xab 0x8>;
		};

		MDP_RSZ0@0x14003000 {
			compatible = "mediatek,MDP_RSZ0";
			reg = <0x14003000 0x1000>;
			interrupts = <0x0 0xac 0x8>;
		};

		MDP_RSZ1@0x14004000 {
			compatible = "mediatek,MDP_RSZ1";
			reg = <0x14004000 0x1000>;
			interrupts = <0x0 0xad 0x8>;
		};

		MDP_RSZ2@0x14005000 {
			compatible = "mediatek,MDP_RSZ2";
			reg = <0x14005000 0x1000>;
			interrupts = <0x0 0xae 0x8>;
		};

		MDP_WDMA@0x14006000 {
			compatible = "mediatek,MDP_WDMA";
			reg = <0x14006000 0x1000>;
			interrupts = <0x0 0xb1 0x8>;
		};

		MDP_WROT0@0x14007000 {
			compatible = "mediatek,MDP_WROT0";
			reg = <0x14007000 0x1000>;
			interrupts = <0x0 0xb2 0x8>;
		};

		MDP_WROT1@0x14008000 {
			compatible = "mediatek,MDP_WROT1";
			reg = <0x14008000 0x1000>;
			interrupts = <0x0 0xb3 0x8>;
		};

		MDP_TDSHP0@0x14009000 {
			compatible = "mediatek,MDP_TDSHP0";
			reg = <0x14009000 0x1000>;
			interrupts = <0x0 0xaf 0x8>;
		};

		MDP_TDSHP1@0x1400A000 {
			compatible = "mediatek,MDP_TDSHP1";
			reg = <0x1400a000 0x1000>;
			interrupts = <0x0 0xb0 0x8>;
		};

		DISP_CONFIG@0x14000000 {
			compatible = "mediatek,DISP_CONFIG";
			reg = <0x14000000 0x1000>;
		};

		MTKFB@bf200000 {
			compatible = "mediatek,MTKFB";
			clocks = <0x14 0x5 0x13 0x1 0x13 0x2 0x13 0x3 0x13 0x4 0x13 0x5 0x13 0x6 0x13 0x7 0x13 0x8 0x13 0x9 0x13 0xa 0x13 0xb 0x13 0xc 0x13 0xd 0x13 0xe 0x13 0xf 0x13 0x10 0x13 0x11 0x13 0x12 0x13 0x13 0x13 0x14 0x13 0x15 0x13 0x16 0x13 0x17 0x13 0x18 0x13 0x19 0x13 0x1a 0x13 0x1b 0x13 0x1c 0x13 0x1d 0x13 0x1e 0x13 0x1f 0x13 0x20 0x13 0x21 0x13 0x22 0x13 0x23 0x13 0x24 0x13 0x25 0x13 0x26 0x13 0x27 0x13 0x28 0x13 0x29 0x13 0x2a 0x13 0x2b 0x13 0x30 0x13 0x31 0x13 0x32 0x5 0x6a 0x6 0x8 0x5 0x3a 0x5 0x3b 0x5 0x3c 0x5 0x3d 0x5 0x74 0x6 0xd 0x5 0x20 0x5 0x21 0x5 0x22>;
			clock-names = "MMSYS_CLK_MTCMOS", "MMSYS_CLK_SMI_COMMON", "MMSYS_CLK_SMI_LARB0", "MMSYS_CLK_CAM_MDP", "MMSYS_CLK_MDP_RDMA0", "MMSYS_CLK_MDP_RDMA1", "MMSYS_CLK_MDP_RSZ0", "MMSYS_CLK_MDP_RSZ1", "MMSYS_CLK_MDP_RSZ2", "MMSYS_CLK_MDP_TDSHP0", "MMSYS_CLK_MDP_TDSHP1", "MMSYS_CLK_MDP_WDMA", "MMSYS_CLK_MDP_WROT0", "MMSYS_CLK_MDP_WROT1", "MMSYS_CLK_FAKE_ENG", "MMSYS_CLK_MUTEX_32K", "MMSYS_CLK_DISP_OVL0", "MMSYS_CLK_DISP_OVL1", "MMSYS_CLK_DISP_RDMA0", "MMSYS_CLK_DISP_RDMA1", "MMSYS_CLK_DISP_RDMA2", "MMSYS_CLK_DISP_WDMA0", "MMSYS_CLK_DISP_WDMA1", "MMSYS_CLK_DISP_COLOR0", "MMSYS_CLK_DISP_COLOR1", "MMSYS_CLK_DISP_AAL", "MMSYS_CLK_DISP_GAMMA", "MMSYS_CLK_DISP_UFOE", "MMSYS_CLK_DISP_SPLIT0", "MMSYS_CLK_DISP_SPLIT1", "MMSYS_CLK_DISP_MERGE", "MMSYS_CLK_DISP_OD", "MMSYS_CLK_DISP_PWM0MM", "MMSYS_CLK_DISP_PWM026M", "MMSYS_CLK_DISP_PWM1MM", "MMSYS_CLK_DISP_PWM126M", "MMSYS_CLK_DSI0_ENGINE", "MMSYS_CLK_DSI0_DIGITAL", "MMSYS_CLK_DSI1_ENGINE", "MMSYS_CLK_DSI1_DIGITAL", "MMSYS_CLK_DPI_PIXEL", "MMSYS_CLK_DPI_ENGINE", "MMSYS_CLK_DPI1_PIXEL", "MMSYS_CLK_DPI1_ENGINE", "MMSYS_CLK_LVDS_PIXEL", "MMSYS_CLK_LVDS_CTS", "MMSYS_CLK_SMI_LARB4", "MMSYS_CLK_MUX_DPI0_SEL", "MMSYS_APMIXED_TVDPLL", "MMSYS_CLK_MUX_TVDPLL_D2", "MMSYS_CLK_MUX_TVDPLL_D4", "MMSYS_CLK_MUX_TVDPLL_D8", "MMSYS_CLK_MUX_TVDPLL_D16", "MMSYS_CLK_MUX_DPILVDS_SEL", "MMSYS_APMIXED_LVDSPLL", "MMSYS_CLK_MUX_LVDSPLL_D2", "MMSYS_CLK_MUX_LVDSPLL_D4", "MMSYS_CLK_MUX_LVDSPLL_D8";
		};

		DISP_OVL@0x1400C000 {
			compatible = "mediatek,DISP_OVL";
			reg = <0x1400c000 0x2000>;
			interrupts = <0x0 0xb4 0x8 0x0 0xb5 0x8>;
		};

		DISP_RDMA@0x1400E000 {
			compatible = "mediatek,DISP_RDMA";
			reg = <0x1400e000 0x3000>;
			interrupts = <0x0 0xb6 0x8 0x0 0xb7 0x8 0x0 0xb8 0x8>;
		};

		DISP_WDMA@0x14011000 {
			compatible = "mediatek,DISP_WDMA";
			reg = <0x14011000 0x2000>;
			interrupts = <0x0 0xb9 0x8 0x0 0xba 0x8>;
		};

		DISP_COLOR@0x14013000 {
			compatible = "mediatek,DISP_COLOR";
			reg = <0x14013000 0x2000>;
			interrupts = <0x0 0xbb 0x8 0x0 0xbc 0x8>;
		};

		DISP_AAL@0x14015000 {
			compatible = "mediatek,DISP_AAL";
			reg = <0x14015000 0x1000>;
			interrupts = <0x0 0xbd 0x8>;
		};

		DISP_OD@0x14023000 {
			compatible = "mediatek,DISP_OD";
			reg = <0x14023000 0x1000>;
			interrupts = <0x0 0xc4 0x8>;
		};

		DISP_GAMMA@0x14016000 {
			compatible = "mediatek,DISP_GAMMA";
			reg = <0x14016000 0x1000>;
			interrupts = <0x0 0xbe 0x8>;
		};

		DISP_MERGE@0x14017000 {
			compatible = "mediatek,DISP_MERGE";
			reg = <0x14017000 0x1000>;
		};

		DISP_SPLIT@0x14018000 {
			compatible = "mediatek,DISP_SPLIT";
			reg = <0x14018000 0x2000>;
		};

		DISP_UFOE@0x1401A000 {
			compatible = "mediatek,DISP_UFOE";
			reg = <0x1401a000 0x1000>;
		};

		DSI0@0x1401B000 {
			compatible = "mediatek,DSI0";
			reg = <0x1401b000 0x1000>;
			interrupts = <0x0 0xc0 0x8>;
		};

		DSI1@0x1401C000 {
			compatible = "mediatek,DSI1";
			reg = <0x1401c000 0x1000>;
			interrupts = <0x0 0xc1 0x8>;
		};

		DPI0@0x1401D000 {
			compatible = "mediatek,DPI0";
			reg = <0x1401d000 0x1000>;
			interrupts = <0x0 0xc2 0x8>;
		};

		DPI1@0x14024000 {
			compatible = "mediatek,DPI1";
			reg = <0x14024000 0x1000>;
			interrupts = <0x0 0xc5 0x8>;
		};

		DISP_PWM@0x1401E000 {
			compatible = "mediatek,DISP_PWM";
			reg = <0x1401e000 0x2000>;
		};

		MM_MUTEX@0x14020000 {
			compatible = "mediatek,MM_MUTEX";
			reg = <0x14020000 0x1000>;
			interrupts = <0x0 0xa9 0x8>;
		};

		DISP_CONFIG2@0x10206000 {
			compatible = "mediatek,DISP_CONFIG2";
			reg = <0x10206000 0x1000>;
		};

		DISP_CONFIG3@0x10000000 {
			compatible = "mediatek,DISP_CONFIG3";
			reg = <0x10000000 0x1000>;
		};

		DISP_IO_DRIVING@0x100020F0 {
			compatible = "mediatek,DISP_IO_DRIVING";
			reg = <0x100020f0 0x1000>;
		};

		DISP_TVDPLL_CFG6@0x100000A0 {
			compatible = "mediatek,DISP_TVDPLL_CFG6";
			reg = <0x100000a0 0x1000>;
		};

		DISP_TVDPLL_CON0@0x1000C270 {
			compatible = "mediatek,DISP_TVDPLL_CON0";
			reg = <0x1000c270 0x1000>;
		};

		DISP_TVDPLL_CON1@0x1000C274 {
			compatible = "mediatek,DISP_TVDPLL_CON1";
			reg = <0x1000c274 0x1000>;
		};

		MIPITX0@0x10215000 {
			compatible = "mediatek,MIPITX0";
			reg = <0x10215000 0x1000>;
		};

		MIPITX1@0x10216000 {
			compatible = "mediatek,MIPITX1";
			reg = <0x10216000 0x1000>;
		};

		SMI_LARB0@0x14021000 {
			compatible = "mediatek,SMI_LARB0";
			reg = <0x14021000 0x1000>;
			interrupts = <0x0 0xc5 0x8>;
		};

		SMI_COMMON@0x14022000 {
			compatible = "mediatek,SMI_COMMON";
			reg = <0x14022000 0x1000 0x14021000 0x1000 0x16010000 0x1000 0x15001000 0x1000 0x18001000 0x1000 0x14027000 0x1000 0x19001000 0x1000>;
			clocks = <0x13 0x1 0x13 0x2 0x18 0x1 0x18 0x2 0x19 0x1 0x1a 0x1 0x1a 0x2 0x13 0x32 0x1b 0x1 0x1b 0x2 0x14 0x5 0x14 0x1 0x14 0x4 0x14 0x3 0x14 0x6>;
			clock-names = "smi_common", "larb0_disp", "larb1_vdec_cken", "larb1_vdec_larb_cken", "larb2_img", "larb3_venc_cken1", "larb3_venc_cken2", "larb4_disp", "larb5_venclt_cken1", "larb5_venclt_cken2", "larb0_mtcmos", "larb1_mtcmos", "larb2_mtcmos", "larb3_mtcmos", "larb5_mtcmos";
		};

		SMI_LARB4@14027000 {
			compatible = "mediatek,SMI_LARB4";
			reg = <0x14027000 0x1000>;
			interrupts = <0x0 0xce 0x8>;
		};

		IMGSYS_CONFIG@0x15000000 {
			compatible = "mediatek,IMGSYS_CONFIG";
			reg = <0x15000000 0x1000>;
		};

		SMI_LARB2@0x15001000 {
			compatible = "mediatek,SMI_LARB2";
			reg = <0x15001000 0x1000>;
			interrupts = <0x0 0xd1 0x8>;
		};

		ISPSYS@0x15000000 {
			compatible = "mediatek,ISPSYS";
			reg = <0x15004000 0x9000 0x1500d000 0x1000 0x15000000 0x10000 0x10217000 0x3000 0x10002000 0x1000>;
			interrupts = <0x0 0xd3 0x8 0x0 0xd4 0x8 0x0 0xd5 0x8 0x0 0xd6 0x8 0x0 0xd7 0x8>;
			clocks = <0x14 0x4 0x19 0x1 0x19 0x2 0x19 0x3 0x19 0x4 0x19 0x5 0x19 0x6 0x19 0x7 0x14 0x5 0x13 0x1>;
			clock-names = "SCP_SYS_ISP", "IMG_LARB2_SMI", "IMG_CAM_SMI", "IMG_CAM_CAM", "IMG_SEN_TG", "IMG_SEN_CAM", "IMG_CAM_SV", "IMG_FD", "SCP_SYS_DIS", "MM_SMI_COMMON";
		};

		camera1@0x15008000 {
			compatible = "mediatek,CAMERA_HW";
			reg = <0x15008000 0x1000>;
			clocks = <0x5 0x5a 0x5 0x4b 0x5 0x43>;
			clock-names = "TOP_CAMTG_SEL", "TOP_UNIVPLL_D26", "TOP_UNIVPLL2_D2";
		};

		camera2@0x15008000 {
			compatible = "mediatek,CAMERA_HW2";
			reg = <0x15008000 0x1000>;
		};

		CAM0@0x15004000 {
			compatible = "mediatek,CAM0";
			reg = <0x15004000 0x2000>;
			interrupts = <0x0 0xd3 0x8>;
		};

		CAM1@0x15006000 {
			compatible = "mediatek,CAM1";
			reg = <0x15006000 0x1000>;
			interrupts = <0x0 0xd4 0x8>;
		};

		CAM2@0x15007000 {
			compatible = "mediatek,CAM2";
			reg = <0x15007000 0x1000>;
			interrupts = <0x0 0xd5 0x8>;
		};

		SENINF@0x15008000 {
			compatible = "mediatek,SENINF";
			reg = <0x15008000 0x1000>;
			interrupts = <0x0 0xd3 0x8>;
		};

		CAMSV0@0x15009000 {
			compatible = "mediatek,CAMSV0";
			reg = <0x15009000 0x800>;
			interrupts = <0x0 0xd6 0x8>;
		};

		CAMSV1@0x15009800 {
			compatible = "mediatek,CAMSV1";
			reg = <0x15009800 0x800>;
			interrupts = <0x0 0xd7 0x8>;
		};

		FD@0x1500B000 {
			compatible = "mediatek,FD";
			reg = <0x1500b000 0x1000>;
			interrupts = <0x0 0xd8 0x8>;
			clocks = <0x14 0x4 0x19 0x7 0x14 0x5 0x13 0x1>;
			clock-names = "SCP_SYS_ISP", "IMG_FD", "SCP_SYS_DIS", "MM_SMI_COMMON";
		};

		MIPI_RX@0x1500C000 {
			compatible = "mediatek,MIPI_RX";
			reg = <0x1500c000 0x1000>;
		};

		CAM0_INNER@0x1500D000 {
			compatible = "mediatek,CAM0_INNER";
			reg = <0x1500d000 0x1000>;
		};

		CAM2_INNER@0x1500E000 {
			compatible = "mediatek,CAM2_INNER";
			reg = <0x1500e000 0x1000>;
		};

		CAM3_INNER@0x1500F000 {
			compatible = "mediatek,CAM3_INNER";
			reg = <0x1500f000 0x1000>;
		};

		VDEC_GCON@16000000 {
			compatible = "mediatek,VDEC_GCON";
			reg = <0x16000000 0x10000>;
			clocks = <0x13 0x1 0x18 0x1 0x18 0x2 0x1a 0x1 0x1a 0x2 0x1b 0x1 0x1b 0x2 0x14 0x1 0x14 0x3 0x14 0x6>;
			clock-names = "MMSYS_CLK_SMI_COMMON", "MT_CG_VDEC0_VDEC", "MT_CG_VDEC1_LARB", "MT_CG_VENC_SMI_LARB3", "MT_CG_VENC_CKE1", "MT_CG_VENCLT_LARB", "MT_CG_VENCLT_CKE", "MT_VDEC_POWER", "MT_VENC_POWER", "MT_VENC_POWER2";
		};

		SMI_LARB1@16010000 {
			compatible = "mediatek,SMI_LARB1";
			reg = <0x16010000 0x10000>;
			interrupts = <0x0 0xcd 0x8>;
		};

		VDEC@16020000 {
			compatible = "mediatek,VDEC";
			reg = <0x16020000 0x10000>;
			interrupts = <0x0 0xcc 0x8>;
		};

		MJC_CONFIG@0x12000000 {
			compatible = "mediatek,MJC_CONFIG";
			reg = <0x12000000 0x1000>;
		};

		MJC_TOP@0x12001000 {
			compatible = "mediatek,MJC_TOP";
			reg = <0x12001000 0x1000>;
			interrupts = <0x0 0xcf 0x8>;
		};

		VENC_GCON@17000000 {
			compatible = "mediatek,VENC_GCON";
			reg = <0x17000000 0x1000>;
		};

		SMI_LARB3@18001000 {
			compatible = "mediatek,SMI_LARB3";
			reg = <0x18001000 0x1000>;
			interrupts = <0x0 0xc7 0x8>;
		};

		VENC@18002000 {
			compatible = "mediatek,VENC";
			reg = <0x18002000 0x1000>;
			interrupts = <0x0 0xc6 0x8>;
		};

		VENCLT@19002000 {
			compatible = "mediatek,VENCLT";
			reg = <0x19002000 0x1000>;
			interrupts = <0x0 0xca 0x8>;
		};

		JPGENC@18003000 {
			compatible = "mediatek,JPGENC";
			reg = <0x18003000 0x1000>;
			interrupts = <0x0 0xc8 0x8>;
			clocks = <0x13 0x1 0x1a 0x1 0x1a 0x2 0x1a 0x3 0x1a 0x4 0x14 0x3>;
			clock-names = "MMSYS_CLK_SMI_COMMON", "MT_CG_VENC_SMI_LARB3", "MT_CG_VENC_CKE", "MT_CG_VENC_JPGENC", "MT_CG_VENC_JPGDEC", "MT_CG_JPG_PWR";
		};

		JPGDEC@18004000 {
			compatible = "mediatek,JPGDEC";
			reg = <0x18004000 0x1000>;
			interrupts = <0x0 0xcb 0x8>;
		};

		SMI_LARB5@19001000 {
			compatible = "mediatek,SMI_LARB5";
			reg = <0x19001000 0x1000>;
			interrupts = <0x0 0xe4 0x8>;
		};

		gpio@0x10001e00 {
			compatible = "mediatek,fpga_gpio";
			reg = <0x10001e00 0x100>;
		};

		HDMI@0x14025000 {
			compatible = "mediatek,hdmitx";
			reg = <0x14025000 0x1000 0x11012000 0x10 0x10013000 0xbc>;
			interrupts = <0x0 0xa7 0x8>;
			clocks = <0x14 0x5 0x4 0x1f 0x13 0x33 0x13 0x34 0x12 0x9 0x13 0x2c 0x13 0x2d 0x13 0x2e 0x13 0x2f 0x5 0x73 0x5 0x4 0x5 0x15 0x5 0x16 0x5 0x76 0x5 0x37 0x5 0x35 0x5 0x44 0x5 0x77 0x5 0x4b 0x5 0x4c 0x5 0x45>;
			clock-names = "mmsys_power", "peri_ddc_pdn", "mmsys_hdmi_hdcp", "mmsys_hdmi_hdcp24", "cec_pdn", "mmsys_hdmi_pll", "mmsys_hdmi_pixel", "mmsys_hdmi_audio", "mmsys_hdmi_spidif", "top_hdmi_sel", "top_hdmisel_dig_cts", "top_hdmisel_d2", "top_hdmisel_d3", "top_hdcp_sel", "top_hdcpsel_sys4d2", "top_hdcpsel_sys3d4", "top_hdcpsel_univ2d2", "top_hdcp24_sel", "top_hdcp24sel_univpd26", "top_hdcp24sel_univpd52", "top_hdcp24sel_univp2d8";
			gpios = <0x15 0x22 0x0>;
		};

		IRRX@0x1100c000 {
			compatible = "mediatek,mtk_irrx";
			reg = <0x1100c000 0xf4>;
			interrupts = <0x0 0x6c 0x4>;
			gpio_set = <0x10005600 0x8>;
			clocks = <0x4 0x22 0x4 0x13>;
			clock-names = "PERISYS PERI_IRRX", "PERISYS PERI_IRDA";
		};

		dcm@0 {
			compatible = "mediatek,mt8173-dcm";
			reg = <0x10000000 0x1000 0x10001000 0x1000 0x10003000 0x1000 0x10004000 0x1000 0x1000d000 0x1000 0x10011000 0x1000 0x10200000 0x1000 0x10203000 0x1000 0x10205000 0x1000 0x10214000 0x1000 0x11007000 0x1000 0x11008000 0x1000 0x11009000 0x1000 0x11010000 0x1000 0x11011000 0x1000 0x11200000 0x1000 0x11230000 0x1000 0x11240000 0x1000 0x11250000 0x1000 0x11260000 0x1000 0x14000000 0x1000 0x14021000 0x1000 0x14022000 0x1000 0x14027000 0x1000 0x15001000 0x1000 0x15004000 0x1000 0x1500b000 0x1000 0x16000000 0x1000 0x16010000 0x1000 0x18001000 0x1000 0x18002000 0x1000 0x18003000 0x1000 0x18004000 0x1000 0x19001000 0x1000 0x19002000 0x1000>;
			clocks = <0x14 0x1 0x14 0x3 0x14 0x4 0x14 0x5 0x14 0x6 0x5 0x55>;
			clock-names = "sys_vde", "sys_ven", "sys_isp", "sys_dis", "sys_ven2", "mm_sel";
		};
	};

	sound {
		compatible = "mediatek,mt-soc-machine";
		#address-cells = <0x2>;
		#size-cells = <0x2>;
		reg = <0x0 0x11220000 0x0 0x1000 0x0 0x11221000 0x0 0x9000>;
		interrupts = <0x0 0x86 0x8>;
		clocks = <0x1c 0x1 0x1c 0x2 0x1c 0xd 0x1c 0xe 0x1c 0xc 0x1c 0xf 0x1c 0x8 0x1c 0x9 0x1c 0x5 0x1c 0x3 0x1c 0x4 0x1c 0x7 0x1c 0x6 0x12 0x3 0x5 0x64 0x5 0x65 0x5 0x6d 0x5 0x6e 0x5 0x19 0x5 0x1a 0x14 0x7 0xe>;
		clock-names = "aud_afe_clk", "aud_i2s_clk", "aud_dac_clk", "aud_dac_predis_clk", "aud_adc_clk", "aud_tml_clk", "aud_hdmi_clk", "aud_spdif_clk", "aud_spdif2_clk", "aud_apll22m_clk", "aud_apll24m_clk", "aud_apll1_tuner_clk", "aud_apll2_tuner_clk", "infra_sys_audio_clk", "top_pdn_audio", "top_pdn_aud_intbus", "top_audio_1_sel", "top_audio_2_sel", "top_apll1_ck", "top_apll2_ck", "scp_sys_audio", "clk26m";
		mediatek,board-channel-type = <0x0>;
	};

	mediatek,mt-soc-dl1-pcm {
		compatible = "mediatek,mt-soc-dl1-pcm";
	};

	mediatek,mt-soc-ul1-pcm {
		compatible = "mediatek,mt-soc-ul1-pcm";
	};

	mediatek,mt-soc-ul2-pcm {
		compatible = "mediatek,mt-soc-ul2-pcm";
	};

	mediatek,mt-soc-btsco-pcm {
		compatible = "mediatek,mt-soc-btsco-pcm";
	};

	mediatek,mt-soc-hdmi-pcm {
		compatible = "mediatek,mt-soc-hdmi-pcm";
	};

	mediatek,mt-soc-dl1-awb-pcm {
		compatible = "mediatek,mt-soc-dl1-awb-pcm";
	};

	mediatek,mt-soc-hdmi-raw {
		compatible = "mediatek,mt-soc-hdmi-raw";
	};

	mediatek,mt-soc-spdif-pcm {
		compatible = "mediatek,mt-soc-spdif-pcm";
	};

	mediatek,mt-soc-i2s0-awb-pcm {
		compatible = "mediatek,mt-soc-i2s0-awb-pcm";
	};

	mediatek,mt-soc-mrgrx-pcm {
		compatible = "mediatek,mt-soc-mrgrx-pcm";
	};

	mediatek,mt-soc-mrgrx-awb-pcm {
		compatible = "mediatek,mt-soc-mrgrx-awb-pcm";
	};

	mediatek,mt-soc-routing-pcm {
		compatible = "mediatek,mt-soc-routing-pcm";
	};

	mediatek,mt-soc-dummy-dai {
		compatible = "mediatek,mt-soc-dummy-dai";
	};

	mediatek,mt-soc-codec {
		compatible = "mediatek,mt-soc-codec";
		mediatek,speaker-mode = <0x0>;
	};

	mediatek,battery_meter {
		compatible = "mediatek,battery_meter";
	};

	mediatek,battery_common {
		compatible = "mediatek,battery_common";
	};

	mediatek,mt-spm {
		compatible = "mediatek,mt-spm";
		big-vproc-supply = <0xa>;
		big-vsram-supply = <0xb>;
		clocks = <0x6 0x1>;
		clock-names = "spm_apmixed_ca15pll";
	};

	psci {
		compatible = "arm,psci";
		method = "smc";
		cpu_suspend = <0x84000001>;
		cpu_off = <0x84000002>;
		cpu_on = <0x84000003>;
		affinity_info = <0x84000004>;
	};

	MSDC1_INS@1 {
		compatible = "mediatek,MSDC1_INS-eint";
		interrupt-parent = <0xf>;
		interrupts = <0x1 0x8>;
		gpio-pullen = <0x10005100 0x2>;
		gpio-pullsel = <0x10005200 0x2>;
		debounce = <0x1 0x3e8>;
	};

	mediatek,mt76xx_wifi_ctrl {
		compatible = "mediatek, mt76xx_wifi_ctrl";
		rst-gpio = <0x68>;
		interrupt-parent = <0xf>;
		interrupts = <0x65 0x8>;
	};

	mediatek,mt76xx_bt_ctrl {
		compatible = "mediatek,mt76xx_bt_ctrl";
		interrupt-parent = <0xf>;
		interrupts = <0x64 0x8>;
		pinctrl-names = "default";
		pinctrl-0 = <0x1d>;
	};
};
